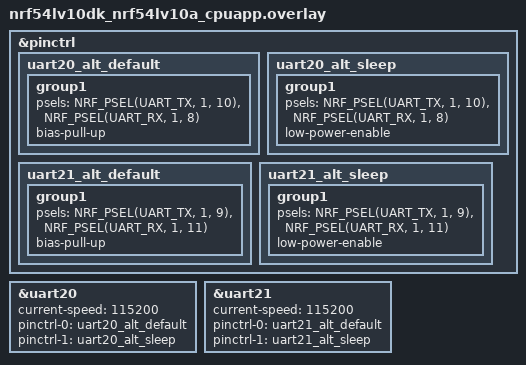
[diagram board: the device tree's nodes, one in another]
/*
 * Copyright (c) 2026 Nordic Semiconductor ASA
 *
 * SPDX-License-Identifier: LicenseRef-Nordic-5-Clause
 */

/*
 * Required loopbacks:
 * P1.10 <-> P1.11
 * P1.08 <-> P1.9
 */

&pinctrl {
	uart20_alt_default: uart20_alt_default {
		group1 {
			psels = <NRF_PSEL(UART_TX, 1, 10)>,
				<NRF_PSEL(UART_RX, 1, 8)>;
			bias-pull-up;
		};
	};

	uart20_alt_sleep: uart20_alt_sleep {
		group1 {
			psels = <NRF_PSEL(UART_TX, 1, 10)>,
				<NRF_PSEL(UART_RX, 1, 8)>;
			low-power-enable;
		};
	};

	uart21_alt_default: uart21_alt_default {
		group1 {
			psels = <NRF_PSEL(UART_TX, 1, 9)>,
				<NRF_PSEL(UART_RX, 1, 11)>;
			bias-pull-up;
		};
	};

	uart21_alt_sleep: uart21_alt_sleep {
		group1 {
			psels = <NRF_PSEL(UART_TX, 1, 9)>,
				<NRF_PSEL(UART_RX, 1, 11)>;
			low-power-enable;
		};
	};
};

dut_uart_a: &uart20 {
	status = "okay";
	current-speed = <115200>;
	pinctrl-0 = <&uart20_alt_default>;
	pinctrl-1 = <&uart20_alt_sleep>;
	pinctrl-names = "default", "sleep";
};

dut_uart_b: &uart21 {
	status = "okay";
	current-speed = <115200>;
	pinctrl-0 = <&uart21_alt_default>;
	pinctrl-1 = <&uart21_alt_sleep>;
	pinctrl-names = "default", "sleep";
};
